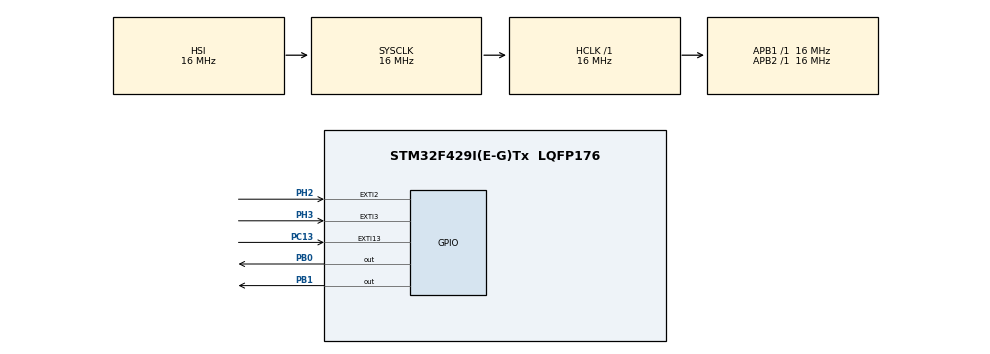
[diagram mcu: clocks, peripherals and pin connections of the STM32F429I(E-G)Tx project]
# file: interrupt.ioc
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Mcu.Family=STM32F4
Mcu.Name=STM32F429I(E-G)Tx
Mcu.Package=LQFP176
NVIC.EXTI15_10_IRQn=true\:1\:0\:true\:false\:true\:true\:true
NVIC.EXTI2_IRQn=true\:1\:0\:true\:false\:true\:true\:true
NVIC.EXTI3_IRQn=true\:1\:0\:true\:false\:true\:true\:true
NVIC.PriorityGroup=NVIC_PRIORITYGROUP_4
NVIC.TIM1_UP_TIM10_IRQn=true\:0\:0\:true\:false\:true\:true\:true
PA13.Mode=Serial_Wire
PA13.Signal=SYS_JTMS-SWDIO
PA14.Mode=Serial_Wire
PA14.Signal=SYS_JTCK-SWCLK
PB0.PinState=GPIO_PIN_SET
PB0.Signal=GPIO_Output
PB1.PinState=GPIO_PIN_RESET
PB1.Signal=GPIO_Output
PC13.GPIO_ModeDefaultEXTI=GPIO_MODE_IT_FALLING
PC13.GPIO_PuPd=GPIO_PULLUP
PC13.Signal=GPXTI13
PH0/OSC_IN.Mode=HSE-External-Oscillator
PH0/OSC_IN.Signal=RCC_OSC_IN
PH1/OSC_OUT.Mode=HSE-External-Oscillator
PH1/OSC_OUT.Signal=RCC_OSC_OUT
PH2.GPIO_ModeDefaultEXTI=GPIO_MODE_IT_FALLING
PH2.GPIO_PuPd=GPIO_PULLUP
PH2.Signal=GPXTI2
PH3.GPIO_ModeDefaultEXTI=GPIO_MODE_IT_FALLING
PH3.GPIO_PuPd=GPIO_PULLUP
PH3.Signal=GPXTI3
ProjectManager.HeapSize=0x200
ProjectManager.StackSize=0x400
ProjectManager.TargetToolchain=MDK-ARM V5.27
RCC.AHBFreq_Value=16000000
RCC.APB1Freq_Value=16000000
RCC.APB1TimFreq_Value=16000000
RCC.APB2Freq_Value=16000000
RCC.APB2TimFreq_Value=16000000
RCC.CortexFreq_Value=16000000
RCC.HCLKFreq_Value=16000000
RCC.HSE_VALUE=25000000
RCC.HSI_VALUE=16000000
RCC.LSE_VALUE=32768
RCC.SYSCLKFreq_VALUE=16000000
RCC.VCOOutputFreq_Value=192000000
TIM1.Period=1000-1
TIM1.Prescaler=16000-1
VP_TIM1_VS_ClockSourceINT.Mode=Internal
board=custom

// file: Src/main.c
/* USER CODE BEGIN Header */
/**
  ******************************************************************************
  * @file           : main.c
  * @brief          : Main program body
  ******************************************************************************
  * @attention
  *
  * <h2><center>&copy; Copyright (c) 2020 STMicroelectronics.
  * All rights reserved.</center></h2>
  *
  * This software component is licensed by ST under BSD 3-Clause license,
  * the "License"; You may not use this file except in compliance with the
  * License. You may obtain a copy of the License at:
  *                        opensource.org/licenses/BSD-3-Clause
  *
  ******************************************************************************
  */
/* USER CODE END Header */

#include "main.h"
#include "tim.h"
#include "gpio.h"

void SystemClock_Config(void);
/* USER CODE BEGIN PFP */
void buling(uint8_t number);
/* USER CODE END PFP */

int main(void)
{

  /* MCU Configuration--------------------------------------------------------*/

  /* Reset of all peripherals, Initializes the Flash interface and the Systick. */
  HAL_Init();

  /* Configure the system clock */
  SystemClock_Config();

  /* Initialize all configured peripherals */
  MX_GPIO_Init();
  MX_TIM1_Init();
  /* USER CODE BEGIN 2 */
	HAL_TIM_Base_Start_IT((TIM_HandleTypeDef *)&htim1);
  /* USER CODE END 2 */

  /* Infinite loop */
  while (1)
  {

  }
}

void SystemClock_Config(void)
{
  RCC_OscInitTypeDef RCC_OscInitStruct = {0};
  RCC_ClkInitTypeDef RCC_ClkInitStruct = {0};

  /** Configure the main internal regulator output voltage
  */
  __HAL_RCC_PWR_CLK_ENABLE();
  __HAL_PWR_VOLTAGESCALING_CONFIG(PWR_REGULATOR_VOLTAGE_SCALE3);
  /** Initializes the CPU, AHB and APB busses clocks
  */
  RCC_OscInitStruct.OscillatorType = RCC_OSCILLATORTYPE_HSI;
  RCC_OscInitStruct.HSIState = RCC_HSI_ON;
  RCC_OscInitStruct.HSICalibrationValue = RCC_HSICALIBRATION_DEFAULT;
  RCC_OscInitStruct.PLL.PLLState = RCC_PLL_NONE;
  if (HAL_RCC_OscConfig(&RCC_OscInitStruct) != HAL_OK)
  {
    Error_Handler();
  }
  /** Initializes the CPU, AHB and APB busses clocks
  */
  RCC_ClkInitStruct.ClockType = RCC_CLOCKTYPE_HCLK|RCC_CLOCKTYPE_SYSCLK
                              |RCC_CLOCKTYPE_PCLK1|RCC_CLOCKTYPE_PCLK2;
  RCC_ClkInitStruct.SYSCLKSource = RCC_SYSCLKSOURCE_HSI;
  RCC_ClkInitStruct.AHBCLKDivider = RCC_SYSCLK_DIV1;
  RCC_ClkInitStruct.APB1CLKDivider = RCC_HCLK_DIV1;
  RCC_ClkInitStruct.APB2CLKDivider = RCC_HCLK_DIV1;

  if (HAL_RCC_ClockConfig(&RCC_ClkInitStruct, FLASH_LATENCY_0) != HAL_OK)
  {
    Error_Handler();
  }
}

/* USER CODE BEGIN 4 */

void buling(uint8_t number)
{
	uint8_t i;
	for(i = 0;i < number;i++)
	{
		HAL_GPIO_TogglePin((GPIO_TypeDef*) GPIOB, (uint16_t) GPIO_PIN_0);
		HAL_Delay(200);
		HAL_GPIO_TogglePin((GPIO_TypeDef*) GPIOB, (uint16_t) GPIO_PIN_0);
		HAL_Delay(200);
	}
}

//这两个函数为回调函数
//void HAL_TIM_PeriodElapsedCallback(TIM_HandleTypeDef *htim)
//{
//	HAL_GPIO_TogglePin((GPIO_TypeDef*) GPIOB, (uint16_t) GPIO_PIN_1);
//}
//void HAL_GPIO_EXTI_Callback(uint16_t GPIO_Pin)
//{
//	if(GPIO_Pin == GPIO_PIN_13)
//		buling(3);
//	else if(GPIO_Pin == GPIO_PIN_2)
//		buling(1);
//	else if(GPIO_Pin == GPIO_PIN_3)
//		buling(2);
//}

/* USER CODE END 4 */

void Error_Handler(void)
{
}

/************************ (C) COPYRIGHT STMicroelectronics *****END OF FILE****/
